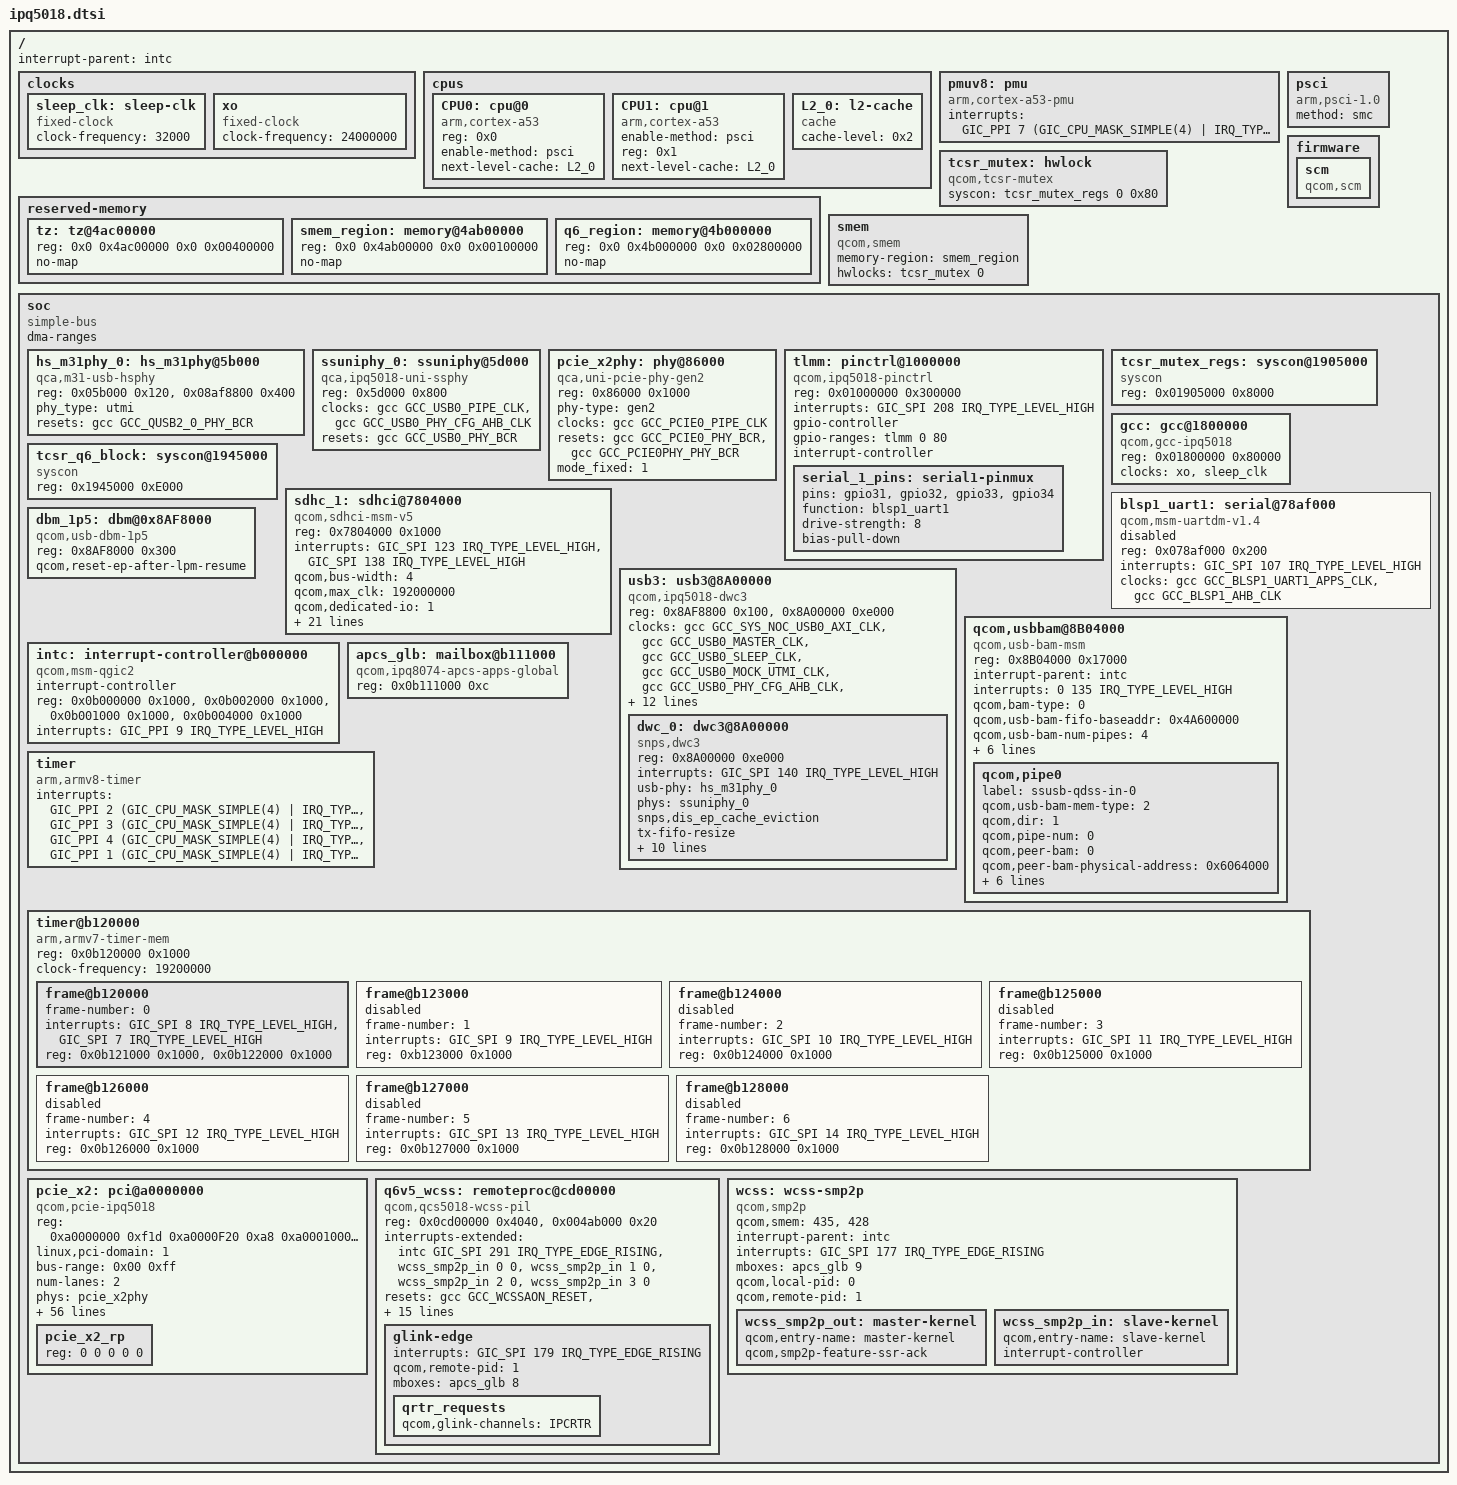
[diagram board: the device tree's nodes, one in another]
// SPDX-License-Identifier: ISC
/*
 * Copyright (c) 2018-2020, The Linux Foundation. All rights reserved.
 */

#include <dt-bindings/interrupt-controller/arm-gic.h>
#include <dt-bindings/clock/qcom,gcc-ipq5018.h>
#include <dt-bindings/reset/qcom,gcc-ipq5018.h>

/ {
	#address-cells = <2>;
	#size-cells = <2>;
	interrupt-parent = <&intc>;

	clocks {
		sleep_clk: sleep-clk {
			compatible = "fixed-clock";
			clock-frequency = <32000>;
			#clock-cells = <0>;
		};

		xo: xo {
			compatible = "fixed-clock";
			clock-frequency = <24000000>;
			#clock-cells = <0>;
		};
	};

	cpus: cpus {
		#address-cells = <1>;
		#size-cells = <0>;

		CPU0: cpu@0 {
			device_type = "cpu";
			compatible = "arm,cortex-a53";
			reg = <0x0>;
			enable-method = "psci";
			next-level-cache = <&L2_0>;
		};

		CPU1: cpu@1 {
			device_type = "cpu";
			compatible = "arm,cortex-a53";
			enable-method = "psci";
			reg = <0x1>;
			next-level-cache = <&L2_0>;
		};

		L2_0: l2-cache {
			compatible = "cache";
			cache-level = <0x2>;
		};
	};

	pmuv8: pmu {
		compatible = "arm,cortex-a53-pmu";
		interrupts = <GIC_PPI 7 (GIC_CPU_MASK_SIMPLE(4) |
					 IRQ_TYPE_LEVEL_HIGH)>;
	};

	psci: psci {
		compatible = "arm,psci-1.0";
		method = "smc";
	};

	firmware {
		scm {
			compatible = "qcom,scm";
		};
	};

	tcsr_mutex: hwlock {
		compatible = "qcom,tcsr-mutex";
		syscon = <&tcsr_mutex_regs 0 0x80>;
		#hwlock-cells = <1>;
	};

	reserved-memory {
		#address-cells = <2>;
		#size-cells = <2>;
		ranges;

		tz: tz@4ac00000 {
			reg = <0x0 0x4ac00000 0x0 0x00400000>;
			no-map;
		};

		smem_region: memory@4ab00000 {
			reg = <0x0 0x4ab00000 0x0 0x00100000>;
			no-map;
		};

		q6_region: memory@4b000000 {
			reg = <0x0 0x4b000000 0x0 0x02800000>;
			no-map;
		};
	};

	smem {
		compatible = "qcom,smem";
		memory-region = <&smem_region>;
		hwlocks = <&tcsr_mutex 0>;
	};

	soc: soc {
		#address-cells = <1>;
		#size-cells = <1>;
		ranges = <0 0 0 0xffffffff>;
		dma-ranges;
		compatible = "simple-bus";

		hs_m31phy_0: hs_m31phy@5b000 {
			compatible = "qca,m31-usb-hsphy";
			reg = <0x05b000 0x120>,
				<0x08af8800 0x400>;
			reg-names = "m31usb_phy_base",
					"qscratch_base";
			phy_type= "utmi";

			resets = <&gcc GCC_QUSB2_0_PHY_BCR>;
			reset-names = "usb2_phy_reset";

			status = "ok";
		};

		ssuniphy_0: ssuniphy@5d000 {
			compatible = "qca,ipq5018-uni-ssphy";
			reg = <0x5d000 0x800>;
			clocks = <&gcc GCC_USB0_PIPE_CLK>,
					<&gcc GCC_USB0_PHY_CFG_AHB_CLK>;

			clock-names = "pipe_clk", "phy_cfg_ahb_clk";

			resets =  <&gcc GCC_USB0_PHY_BCR>;
			reset-names = "por_rst";
			#phy-cells = <0>;
			status = "ok";
		};

		pcie_x2phy: phy@86000{
			compatible = "qca,uni-pcie-phy-gen2";
			reg = <0x86000 0x1000>;
			phy-type = "gen2";
			#phy-cells = <0>;
			clocks = <&gcc GCC_PCIE0_PIPE_CLK>;
			clock-names = "pipe_clk";

			resets = <&gcc GCC_PCIE0_PHY_BCR>,
				<&gcc GCC_PCIE0PHY_PHY_BCR>;
			reset-names = "phy",
					"phy_phy";
			mode_fixed = <1>;
			status = "ok";
		};

		tlmm: pinctrl@1000000 {
			compatible = "qcom,ipq5018-pinctrl";
			reg = <0x01000000 0x300000>;
			interrupts = <GIC_SPI 208 IRQ_TYPE_LEVEL_HIGH>;
			gpio-controller;
			#gpio-cells = <2>;
			gpio-ranges = <&tlmm 0 80>;
			interrupt-controller;
			#interrupt-cells = <2>;

			serial_1_pins: serial1-pinmux {
				pins = "gpio31", "gpio32", "gpio33", "gpio34";
				function = "blsp1_uart1";
				drive-strength = <8>;
				bias-pull-down;
			};
		};

		tcsr_mutex_regs: syscon@1905000 {
			compatible = "syscon";
			reg = <0x01905000 0x8000>;
		};

		gcc: gcc@1800000 {
			compatible = "qcom,gcc-ipq5018";
			reg = <0x01800000 0x80000>;
			clocks = <&xo>, <&sleep_clk>;
			clock-names = "xo", "sleep_clk";
			#clock-cells = <1>;
			#reset-cells = <1>;
		};

		tcsr_q6_block: syscon@1945000 {
			compatible = "syscon";
			reg = <0x1945000 0xE000>;
		};

	sdhc_1: sdhci@7804000 {
			compatible = "qcom,sdhci-msm-v5";
			reg = <0x7804000 0x1000>;
			reg-names = "hc_mem";

			interrupts = <GIC_SPI 123 IRQ_TYPE_LEVEL_HIGH>,
				   <GIC_SPI 138 IRQ_TYPE_LEVEL_HIGH>;
			interrupt-names = "hc_irq", "pwr_irq";

			qcom,bus-width = <4>;
			qcom,max_clk = <192000000>;
			qcom,dedicated-io = <1>;

			/* device core power supply */
			qcom,vdd-voltage-level = <2900000 2900000>;
			qcom,vdd-current-level = <200 570000>;

			/* device communication power supply */
			qcom,vdd-io-lpm-sup;
			qcom,vdd-io-voltage-level = <1800000 1800000>;
			qcom,vdd-io-current-level = <200 325000>;
			qcom,vdd-io-always-on;

			qcom,cpu-dma-latency-us = <701>;
			qcom,msm-bus,name = "sdhc1";
			qcom,msm-bus,num-cases = <9>;
			qcom,msm-bus,num-paths = <1>;
			qcom,msm-bus,vectors-KBps = <78 512 0 0>, /* No vote */
				<78 512 1046 3200>,    /* 400 KB/s*/
				<78 512 52286 160000>, /* 20 MB/s */
				<78 512 65360 200000>, /* 25 MB/s */
				<78 512 130718 400000>, /* 50 MB/s */
				<78 512 261438 800000>, /* 100 MB/s */
				<78 512 261438 800000>, /* 200 MB/s */
				<78 512 261438 800000>, /* 400 MB/s */
				<78 512 1338562 4096000>; /* Max. bandwidth */
			qcom,bus-bw-vectors-bps = <0 400000 20000000 25000000 \
						  50000000 100000000 200000000 \
						  400000000 4294967295>;

			clocks = <&gcc GCC_SDCC1_AHB_CLK>,
			       <&gcc GCC_SDCC1_APPS_CLK>;
			clock-names = "iface", "core";
			qcom,large-address-bus;
			qcom,disable-aggressive-pm;
			status = "ok";
		};

		blsp1_uart1: serial@78af000 {
			compatible = "qcom,msm-uartdm-v1.4", "qcom,msm-uartdm";
			reg = <0x078af000 0x200>;
			interrupts = <GIC_SPI 107 IRQ_TYPE_LEVEL_HIGH>;
			clocks = <&gcc GCC_BLSP1_UART1_APPS_CLK>,
				<&gcc GCC_BLSP1_AHB_CLK>;
			clock-names = "core", "iface";
			status = "disabled";
		};

		usb3: usb3@8A00000 {
			compatible = "qcom,ipq5018-dwc3";
			#address-cells = <1>;
			#size-cells = <1>;
			ranges;
			reg = <0x8AF8800 0x100>,
				<0x8A00000 0xe000>;
			reg-names = "qscratch_base", "dwc3_base";
			clocks = <&gcc GCC_SYS_NOC_USB0_AXI_CLK>,
				<&gcc GCC_USB0_MASTER_CLK>,
				<&gcc GCC_USB0_SLEEP_CLK>,
				<&gcc GCC_USB0_MOCK_UTMI_CLK>,
				<&gcc GCC_USB0_PHY_CFG_AHB_CLK>,
				<&gcc GCC_USB0_AUX_CLK>,
				<&gcc GCC_USB0_LFPS_CLK>,
				<&gcc GCC_USB0_PIPE_CLK>;
			clock-names = "sys_noc_axi",
				"master",
				"sleep",
				"mock_utmi",
				"cfg_ahb_clk",
				"aux_clk",
				"lfps_clk",
				"pipe_clk";
			assigned-clocks = <&gcc GCC_SYS_NOC_USB0_AXI_CLK>,
					<&gcc GCC_USB0_MASTER_CLK>,
					<&gcc GCC_USB0_MOCK_UTMI_CLK>;
			assigned-clock-rates = <133330000>,
					<133330000>,
					<60000000>;
			resets = <&gcc GCC_USB0_BCR>;
			reset-names = "usb30_mstr_rst";
			qca,host = <1>;
			qcom,usb-dbm = <&dbm_1p5>;
			status = "ok";
			qcom,multiplexed-phy;
			qcom,phy-mux-regs = <&tcsr_q6_block 0x2540>;

			dwc_0: dwc3@8A00000 {
				compatible = "snps,dwc3";
				reg = <0x8A00000 0xe000>;
				interrupts = <GIC_SPI 140 IRQ_TYPE_LEVEL_HIGH>;
				usb-phy = <&hs_m31phy_0>;
				#phy-cells = <0>;
				phys = <&ssuniphy_0>;
				phy-names = "usb3-phy";
				snps,dis_ep_cache_eviction;
				tx-fifo-resize;
				snps,usb3-u1u2-disable;
				snps,nominal-elastic-buffer;
				snps,is-utmi-l1-suspend;
				snps,hird-threshold = /bits/ 8 <0x0>;
				snps,dis_u2_susphy_quirk;
				snps,dis_u3_susphy_quirk;
				snps,quirk-ref-clock-adjustment = <0x49459>;
				snps,quirk-ref-clock-period = <0x10>;
				snps,quirk-30m-sb-sel = <0x0>;
				dr_mode = "host";
			};
		};

		dbm_1p5: dbm@0x8AF8000 {
			compatible = "qcom,usb-dbm-1p5";
			reg = <0x8AF8000 0x300>;
			qcom,reset-ep-after-lpm-resume;
		};

		qcom,usbbam@8B04000 {
			compatible = "qcom,usb-bam-msm";
			reg = <0x8B04000 0x17000>;
			interrupt-parent = <&intc>;
			interrupts = <0 135 IRQ_TYPE_LEVEL_HIGH>;

			qcom,bam-type = <0>;
			qcom,usb-bam-fifo-baseaddr = <0x4A600000>;
			qcom,usb-bam-num-pipes = <4>;
			qcom,ignore-core-reset-ack;
			qcom,disable-clk-gating;
			qcom,usb-bam-override-threshold = <0x4001>;
			qcom,usb-bam-max-mbps-highspeed = <400>;
			qcom,usb-bam-max-mbps-superspeed = <3600>;
			qcom,reset-bam-on-connect;

			qcom,pipe0 {
				label = "ssusb-qdss-in-0";
				qcom,usb-bam-mem-type = <2>;
				qcom,dir = <1>;
				qcom,pipe-num = <0>;
				qcom,peer-bam = <0>;
				qcom,peer-bam-physical-address = <0x6064000>;
				qcom,src-bam-pipe-index = <0>;
				qcom,dst-bam-pipe-index = <0>;
				qcom,data-fifo-offset = <0x0>;
				qcom,data-fifo-size = <0xe00>;
				qcom,descriptor-fifo-offset = <0xe00>;
				qcom,descriptor-fifo-size = <0x200>;
			};
		};

		intc: interrupt-controller@b000000 {
			compatible = "qcom,msm-qgic2";
			interrupt-controller;
			#interrupt-cells = <0x3>;
			reg =   <0x0b000000 0x1000>,  /*GICD*/
				<0x0b002000 0x1000>,  /*GICC*/
				<0x0b001000 0x1000>,  /*GICH*/
				<0x0b004000 0x1000>;  /*GICV*/
			interrupts = <GIC_PPI 9 IRQ_TYPE_LEVEL_HIGH>;
		};

		apcs_glb: mailbox@b111000 {
			compatible = "qcom,ipq8074-apcs-apps-global";
			reg = <0x0b111000 0xc>;

			#mbox-cells = <1>;
		};

		timer {
			compatible = "arm,armv8-timer";
			interrupts = <GIC_PPI 2 (GIC_CPU_MASK_SIMPLE(4) | IRQ_TYPE_LEVEL_LOW)>,
				     <GIC_PPI 3 (GIC_CPU_MASK_SIMPLE(4) | IRQ_TYPE_LEVEL_LOW)>,
				     <GIC_PPI 4 (GIC_CPU_MASK_SIMPLE(4) | IRQ_TYPE_LEVEL_LOW)>,
				     <GIC_PPI 1 (GIC_CPU_MASK_SIMPLE(4) | IRQ_TYPE_LEVEL_LOW)>;
		};

		timer@b120000 {
			#address-cells = <1>;
			#size-cells = <1>;
			ranges;
			compatible = "arm,armv7-timer-mem";
			reg = <0x0b120000 0x1000>;
			clock-frequency = <19200000>;

			frame@b120000 {
				frame-number = <0>;
				interrupts = <GIC_SPI 8 IRQ_TYPE_LEVEL_HIGH>,
					     <GIC_SPI 7 IRQ_TYPE_LEVEL_HIGH>;
				reg = <0x0b121000 0x1000>,
				      <0x0b122000 0x1000>;
			};

			frame@b123000 {
				frame-number = <1>;
				interrupts = <GIC_SPI 9 IRQ_TYPE_LEVEL_HIGH>;
				reg = <0xb123000 0x1000>;
				status = "disabled";
			};

			frame@b124000 {
				frame-number = <2>;
				interrupts = <GIC_SPI 10 IRQ_TYPE_LEVEL_HIGH>;
				reg = <0x0b124000 0x1000>;
				status = "disabled";
			};

			frame@b125000 {
				frame-number = <3>;
				interrupts = <GIC_SPI 11 IRQ_TYPE_LEVEL_HIGH>;
				reg = <0x0b125000 0x1000>;
				status = "disabled";
			};

			frame@b126000 {
				frame-number = <4>;
				interrupts = <GIC_SPI 12 IRQ_TYPE_LEVEL_HIGH>;
				reg = <0x0b126000 0x1000>;
				status = "disabled";
			};

			frame@b127000 {
				frame-number = <5>;
				interrupts = <GIC_SPI 13 IRQ_TYPE_LEVEL_HIGH>;
				reg = <0x0b127000 0x1000>;
				status = "disabled";
			};

			frame@b128000 {
				frame-number = <6>;
				interrupts = <GIC_SPI 14 IRQ_TYPE_LEVEL_HIGH>;
				reg = <0x0b128000 0x1000>;
				status = "disabled";
			};
		};

		pcie_x2: pci@a0000000 {
			compatible = "qcom,pcie-ipq5018";
			reg =  <0xa0000000 0xf1d
				0xa0000F20 0xa8
				0xa0001000 0x1000
				0x80000 0x3000
				0xa0100000 0x1000>;
			reg-names = "dbi", "elbi", "atu", "parf", "config";
			device_type = "pci";
			linux,pci-domain = <1>;
			bus-range = <0x00 0xff>;
			num-lanes = <2>;
			#address-cells = <3>;
			#size-cells = <2>;

			phys = <&pcie_x2phy>;
			phy-names ="pciephy";
			force_gen2 = <1>;

			ranges = <0x81000000 0 0xa0200000 0xa0200000
				  0 0x00100000   /* downstream I/O */
				  0x82000000 0 0xa0300000 0xa0300000
				  0 0x10000000>; /* non-prefetchable memory */

			interrupts = <GIC_SPI 52 IRQ_TYPE_LEVEL_HIGH>,
				<0 448 IRQ_TYPE_LEVEL_HIGH>, <0 449 IRQ_TYPE_LEVEL_HIGH>,
				<0 450 IRQ_TYPE_LEVEL_HIGH>, <0 451 IRQ_TYPE_LEVEL_HIGH>,
				<0 452 IRQ_TYPE_LEVEL_HIGH>, <0 453 IRQ_TYPE_LEVEL_HIGH>,
				<0 454 IRQ_TYPE_LEVEL_HIGH>, <0 455 IRQ_TYPE_LEVEL_HIGH>,
				<0 456 IRQ_TYPE_LEVEL_HIGH>, <0 457 IRQ_TYPE_LEVEL_HIGH>,
				<0 458 IRQ_TYPE_LEVEL_HIGH>, <0 459 IRQ_TYPE_LEVEL_HIGH>,
				<0 460 IRQ_TYPE_LEVEL_HIGH>, <0 461 IRQ_TYPE_LEVEL_HIGH>,
				<0 462 IRQ_TYPE_LEVEL_HIGH>, <0 463 IRQ_TYPE_LEVEL_HIGH>,
				<0 464 IRQ_TYPE_LEVEL_HIGH>, <0 465 IRQ_TYPE_LEVEL_HIGH>,
				<0 466 IRQ_TYPE_LEVEL_HIGH>, <0 467 IRQ_TYPE_LEVEL_HIGH>,
				<0 468 IRQ_TYPE_LEVEL_HIGH>, <0 469 IRQ_TYPE_LEVEL_HIGH>,
				<0 470 IRQ_TYPE_LEVEL_HIGH>, <0 471 IRQ_TYPE_LEVEL_HIGH>,
				<0 472 IRQ_TYPE_LEVEL_HIGH>, <0 473 IRQ_TYPE_LEVEL_HIGH>,
				<0 474 IRQ_TYPE_LEVEL_HIGH>, <0 475 IRQ_TYPE_LEVEL_HIGH>,
				<0 476 IRQ_TYPE_LEVEL_HIGH>, <0 477 IRQ_TYPE_LEVEL_HIGH>,
				<0 478 IRQ_TYPE_LEVEL_HIGH>, <0 479 IRQ_TYPE_LEVEL_HIGH>;
			interrupt-names = "msi", "msi_0", "msi_1",
					"msi_2", "msi_3", "msi_4",
					"msi_5", "msi_6", "msi_7",
					"msi_8", "msi_9", "msi_10",
					"msi_11", "msi_12", "msi_13",
					"msi_14", "msi_15", "msi_16",
					"msi_17", "msi_18", "msi_19",
					"msi_20", "msi_21", "msi_22",
					"msi_23", "msi_24", "msi_25",
					"msi_26", "msi_27", "msi_28",
					"msi_29", "msi_30", "msi_31";
			#interrupt-cells = <1>;
			interrupt-map-mask = <0 0 0 0x7>;
			interrupt-map = <0 0 0 1 &intc 0 75
					 IRQ_TYPE_LEVEL_HIGH>, /* int_a */
					<0 0 0 2 &intc 0 78
					 IRQ_TYPE_LEVEL_HIGH>, /* int_b */
					<0 0 0 3 &intc 0 79
					 IRQ_TYPE_LEVEL_HIGH>, /* int_c */
					<0 0 0 4 &intc 0 83
					 IRQ_TYPE_LEVEL_HIGH>; /* int_d */

			clocks = <&gcc GCC_SYS_NOC_PCIE0_AXI_CLK>,
				 <&gcc GCC_PCIE0_AXI_M_CLK>,
				 <&gcc GCC_PCIE0_AXI_S_CLK>,
				 <&gcc GCC_PCIE0_AHB_CLK>,
				 <&gcc GCC_PCIE0_AUX_CLK>,
				 <&gcc GCC_PCIE0_AXI_S_BRIDGE_CLK>;

			clock-names = "iface",
				      "axi_m",
				      "axi_s",
				      "ahb",
				      "aux",
				      "axi_bridge";

			resets = <&gcc GCC_PCIE0_PIPE_ARES>,
				 <&gcc GCC_PCIE0_SLEEP_ARES>,
				 <&gcc GCC_PCIE0_CORE_STICKY_ARES>,
				 <&gcc GCC_PCIE0_AXI_MASTER_ARES>,
				 <&gcc GCC_PCIE0_AXI_SLAVE_ARES>,
				 <&gcc GCC_PCIE0_AHB_ARES>,
				 <&gcc GCC_PCIE0_AXI_MASTER_STICKY_ARES>,
				 <&gcc GCC_PCIE0_AXI_SLAVE_STICKY_ARES>;

			reset-names = "pipe",
				      "sleep",
				      "sticky",
				      "axi_m",
				      "axi_s",
				      "ahb",
				      "axi_m_sticky",
				      "axi_s_sticky";

			qcom,msi-gicm-addr = <0x0B00B040>;
			qcom,msi-gicm-base = <0x1e0>;

			status = "ok";

			pcie_x2_rp: pcie_x2_rp {
				reg = <0 0 0 0 0>;
			};
		};

		q6v5_wcss: remoteproc@cd00000 {
			compatible = "qcom,qcs5018-wcss-pil";
			reg = <0x0cd00000 0x4040>,
				<0x004ab000 0x20>;
			reg-names = "qdsp6",
				    "rmb";
			interrupts-extended = <&intc GIC_SPI 291 IRQ_TYPE_EDGE_RISING>,
					      <&wcss_smp2p_in 0 0>,
					      <&wcss_smp2p_in 1 0>,
					      <&wcss_smp2p_in 2 0>,
					      <&wcss_smp2p_in 3 0>;
			interrupt-names = "wdog",
					  "fatal",
					  "ready",
					  "handover",
					  "stop-ack";

			resets = <&gcc GCC_WCSSAON_RESET>,
				 <&gcc GCC_WCSS_BCR>,
				 <&gcc GCC_WCSS_Q6_BCR>,
				 <&gcc GCC_CE_BCR>;

			reset-names = "wcss_aon_reset",
				      "wcss_reset",
				      "wcss_q6_reset",
				      "ce_reset";


                        clocks = <&gcc GCC_Q6_AXIS_CLK>,
                                        <&gcc GCC_WCSS_AHB_S_CLK>,
                                        <&gcc GCC_WCSS_ECAHB_CLK>,
                                        <&gcc GCC_WCSS_ACMT_CLK>,
                                        <&gcc GCC_WCSS_AXI_M_CLK>,
                                        <&gcc GCC_Q6_AXIM_CLK>,
                                        <&gcc GCC_Q6_AXIM2_CLK>,
                                        <&gcc GCC_Q6_AHB_CLK>,
                                        <&gcc GCC_Q6_AHB_S_CLK>,
                                        <&gcc GCC_WCSS_AXI_S_CLK>;
                        clock-names = "gcc_q6_axis_clk",
                                        "gcc_wcss_ahb_s_clk",
                                        "gcc_wcss_ecahb_clk",
                                        "gcc_wcss_acmt_clk",
                                        "gcc_wcss_axi_m_clk",
                                        "gcc_q6_axim_clk",
                                        "gcc_q6_axim2_clk",
                                        "gcc_q6_ahb_clk",
                                        "gcc_q6_ahb_s_clk",
                                        "gcc_wcss_axi_s_clk";

			qcom,halt-regs = <&tcsr_q6_block 0xa000 0xd000 0x0>;

			qcom,smem-states = <&wcss_smp2p_out 0>,
					   <&wcss_smp2p_out 1>;
			qcom,smem-state-names = "shutdown",
						"stop";

			memory-region = <&q6_region>;

			glink-edge {
				interrupts = <GIC_SPI 179 IRQ_TYPE_EDGE_RISING>;
				qcom,remote-pid = <1>;
				mboxes = <&apcs_glb 8>;

				qrtr_requests {
					qcom,glink-channels = "IPCRTR";
				};
			};
		};

		wcss: wcss-smp2p {
			compatible = "qcom,smp2p";
			qcom,smem = <435>, <428>;

			interrupt-parent = <&intc>;
			interrupts = <GIC_SPI 177 IRQ_TYPE_EDGE_RISING>;

			mboxes = <&apcs_glb 9>;

			qcom,local-pid = <0>;
			qcom,remote-pid = <1>;

			wcss_smp2p_out: master-kernel {
				qcom,entry-name = "master-kernel";
				qcom,smp2p-feature-ssr-ack;
				#qcom,smem-state-cells = <1>;
			};

			wcss_smp2p_in: slave-kernel {
				qcom,entry-name = "slave-kernel";
				interrupt-controller;
				#interrupt-cells = <2>;
			};
		};
	};
};
